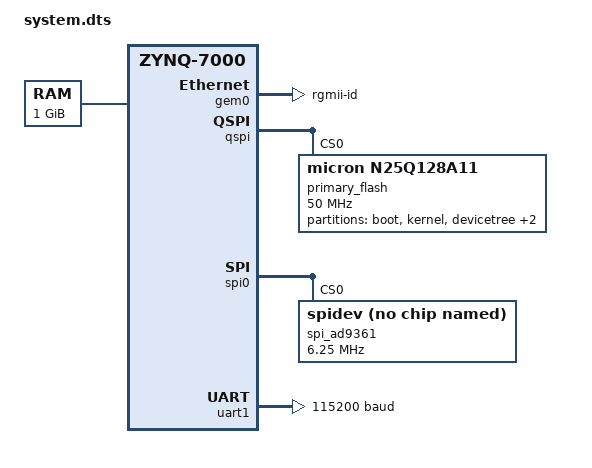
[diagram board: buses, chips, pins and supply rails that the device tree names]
/*
 * CAUTION: This file is automatically generated by Xilinx.
 * Version: HSI 2016.2
 * Today is: Thu Aug 31 14:03:03 2017
*/


/dts-v1/;
/include/ "zynq-7000.dtsi"
/include/ "pl.dtsi"
/ {
	cpus {
		cpu@0 {
			operating-points = <666666 1000000 333333 1000000>;
		};
	};
	chosen {
		bootargs = "console=ttyPS0,115200 earlyprintk uio_pdrv_genirq.of_id=generic-uio";
	};
	aliases {
		ethernet0 = &gem0;
		serial0 = &uart1;
		spi0 = &qspi;
		spi1 = &spi0;
	};
	memory {
		device_type = "memory";
		reg = <0x0 0x40000000>;
	};
};
&gem0 {
	local-mac-address = [00 0a 35 00 00 00];
	phy-mode = "rgmii-id";
	status = "okay";
	xlnx,ptp-enet-clock = <0x69f6bcb>;
};
&gpio0 {
	emio-gpio-width = <64>;
	gpio-mask-high = <0x0>;
	gpio-mask-low = <0x5600>;
};
&intc {
	num_cpus = <2>;
	num_interrupts = <96>;
};
&qspi {
	is-dual = <0>;
	num-cs = <1>;
	status = "okay";
	primary_flash: ps7-qspi@0 {
		#address-cells = <1>;
		#size-cells = <1>;
		compatible = "micron,n25q128a11", "spansion,s25fl256s1", "jedec,spi-nor";
		reg = <0>;
		spi-max-frequency = <50000000>;
		partition@0x000000 {
			label = "boot";
			reg = <0x00000000 0x00700000>;
		};
		partition@0x700000 {
			label = "kernel";
			reg = <0x00700000 0x00400000>;
		};
		partition@0xB00000 {
			label = "devicetree";
			reg = <0x00B00000 0x00020000>;
		};
		partition@0xB20000 {
			label = "rootfs";
			reg = <0x00B20000 0x01000000>;
		};
		partition@0x1B20000 {
			label = "configs";
			reg = <0x01B20000 0x00100000>;
		};
	};
};
&spi0 {
	is-decoded-cs = <0>;
	num-cs = <3>;
	status = "okay";
	spi_ad9361: spi@0 {
		#address-cells = <1>;
		#size-cells = <0>;
		compatible = "spidev";
		spi-max-frequency = <6250000>;
		reg = <0>;
	};
};
&uart1 {
	current-speed = <115200>;
	device_type = "serial";
	port-number = <0>;
	status = "okay";
};
&clkc {
	fclk-enable = <0x3>;
	ps-clk-frequency = <33333333>;
};
